# A31M22x register map
Vendor: ABOV Semiconductor Co., Ltd.; File version: 1.0
CPU: CM0PLUS r0p1, little endian, no MPU, no FPU, VTOR, 2 interrupt priority bits
Registers are 32-bit, read-write, reset 0x0 unless marked. A register's access mark holds for its fields unless they carry their own. Offsets are from the block's base; [hi:lo] are bit positions.

## PORTEN — Port Access Enable Register
Base 0x42000FF0
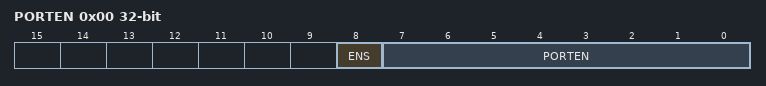
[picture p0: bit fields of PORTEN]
0x00 PORTEN wo (reset mask 0xFF) — Port Access Enable Register
  [8] ENS ro — Enable Status Bit
  [7:0] PORTEN — Port Access Enable bit, write sequence 0x15, 0x51

## SRAM — SRAM MEMORY CONTROLLER
Base 0x41003000
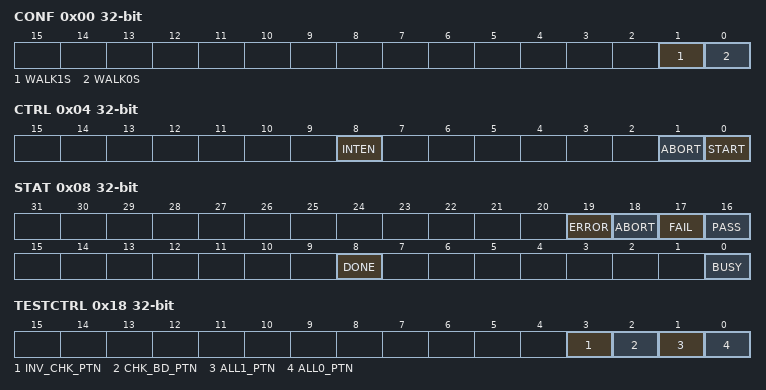
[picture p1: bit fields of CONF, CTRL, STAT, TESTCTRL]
0x00 CONF — SRAM Memory Configuration Register
  [1] WALK1S — Walking 1s algorithm enable
  [0] WALK0S — Walking 0s algorithm enable
0x04 CTRL — SRAM Memory Control Register
  [8] INTEN — SRAM Interrupt enable
  [1] ABORT — Fault Test Abort enable
  [0] START — Fault Test START enable
0x08 STAT — SRAM Memory Status Register
  [19] ERROR — fault test start without WALK0S and walking 1s algorithm enable Status
  [18] ABORT — Interrupt Abort Status
  [17] FAIL — Interrupt Fail Status
  [16] PASS — Interrupt Pass Status
  [8] DONE — Fault Test Done Status
  [0] BUSY ro — Fault Test Busy Status
0x0C FTFADDR ro — SRAM FAULT TEST FAIL ADDRESS Register
  [12:0] FTFADDR — SRAM Fault Test Fail Address
0x10 FTFBITR ro — SRAM FAULT TEST FAIL BIT Register
  [31:0] FTFBIT — SRAM Fault Test Fail Bit
0x14 FTFPADDR ro — SRAM Fault Test Fail PTR Address Register
  [12:0] FTFPADDR — SRAM Fault Test Fail PTR Address
0x18 TESTCTRL — SRAM TEST Control Register
  [3] INV_CHK_PTN — inverse check-board write/status
  [2] CHK_BD_PTN — check-board pattern write/status
  [1] ALL1_PTN — All 1 pattern write/status
  [0] ALL0_PTN — All 0 pattern write/status

## DMA0 — Direct Memory Access Control 0
Base 0x40000400
Same registers: DMA1 0x40000410, DMA2 0x40000420, DMA3 0x40000430
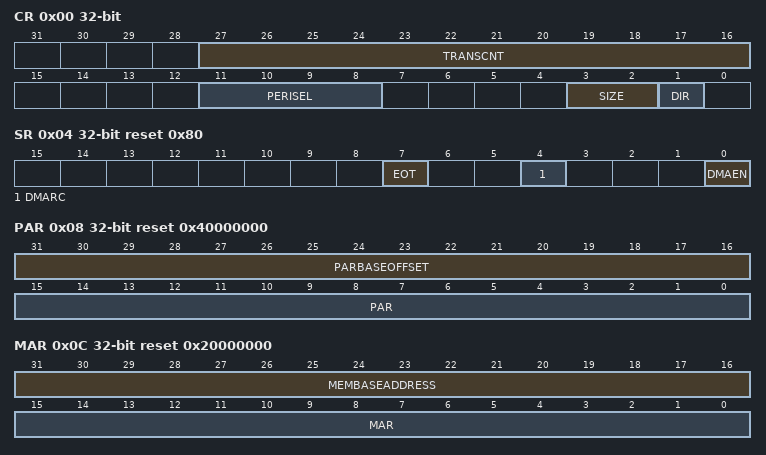
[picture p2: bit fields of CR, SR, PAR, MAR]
0x00 CR — DMA Control Register
  [27:16] TRANSCNT — DMA Transmit counter
  [11:8] PERISEL — Peripheral selection Bit
  [3:2] SIZE — Bus Transmit Size
    0=Byte (transmit byte size); 1=half_word (transmit half word size); 2=word (transmit word size)
  [1] DIR — Transmit direction selection bit
    0=MEM-PERI (Memory->Peripheral); 1=PERI-MEM (Peripheral->Memory)
0x04 SR reset 0x80 — DMA Status Register
  [7] EOT ro — Transmit is over
  [4] DMARC — DMA Request Clear Bit(Auto Clear)
  [0] DMAEN — DMA Enable Bit
0x08 PAR reset 0x40000000 — DMA Peripheral address register
  [31:16] PARBASEOFFSET ro — Peripheral Base Offset
  [15:0] PAR — Peripheral address bit
0x0C MAR reset 0x20000000 — DMA Memory address register
  [31:16] MEMBASEADDRESS ro — Memory Base Address
  [15:0] MAR — Purpose Memory Address

## WDT — WATCH-DOG TIMER
Base 0x40000200
0x00 LR — WDT Load Register
  [31:0] LR — WDT Load Value Bits
0x04 CNT ro reset 0x7A12 — WDT Current Count Register
  [31:0] CNT — Watch-dog Timer Counter Value Bits
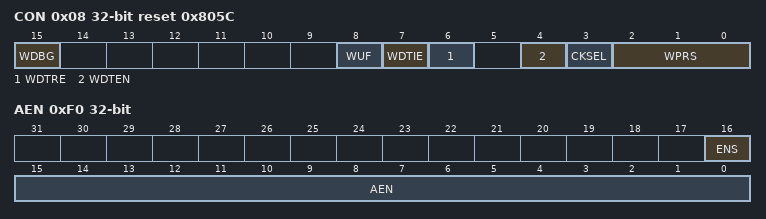
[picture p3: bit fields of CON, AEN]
0x08 CON reset 0x805C — WDT Control Register
  [15] WDBG — Watch-dog Timer Control in debugging mode
  [8] WUF — Watch-dog Timer Underflow Flag Bit, when write WDTLR register, this bit is cleared.
  [7] WDTIE — Watch-dog Timer Underflow Interrupt Enable bit
  [6] WDTRE — Watch-dog Timer Underflow Reset Enable bit
  [4] WDTEN — Watch-dog Timer Counter Enable bit
  [3] CKSEL — Watch-dog Timer Clock Source selection Bit
  [2:0] WPRS — Watch-dog Timer Counter Clock Prescaler bit
    0=WDTCLKIN_DIV_BY_1 (WDT Input Clock divide by 1); 1=WDTCLKIN_DIV_BY_4 (WDT Input Clock divide by 4); 2=WDTCLKIN_DIV_BY_8 (WDT Input Clock divide by 8); 3=WDTCLKIN_DIV_BY_16 (WDT Input Clock divide by 16); 4=WDTCLKIN_DIV_BY_32 (WDT Input Clock divide by 32); 5=WDTCLKIN_DIV_BY_64 (WDT Input Clock divide by 64); 6=WDTCLKIN_DIV_BY_128 (WDT Input Clock divide by 128); 7=WDTCLKIN_DIV_BY_256 (WDT Input Clock divide by 256)
0xF0 AEN — WDT Access Enable Register
  [16] ENS ro — Enable status bit
  [15:0] AEN wo — WDT Master Lock Enable Register (Access = 0xA55A, Reload = 0x555A)
